# ATSAM3N00B device description
Architecture: CORTEX-M3; Family: SAM3; Series: SAM3N
Registers are 32-bit, read-write, no defined reset value unless marked. A register's access mark holds for its fields unless they carry their own. Offsets are from the block's base; [hi:lo] are bit positions; {n}, {i} and the like mark numbered series; 'fields as' and 'values as' point back to an identical list.

## EFC — Embedded Flash Controller
Instances: EFC 0x400E0A00
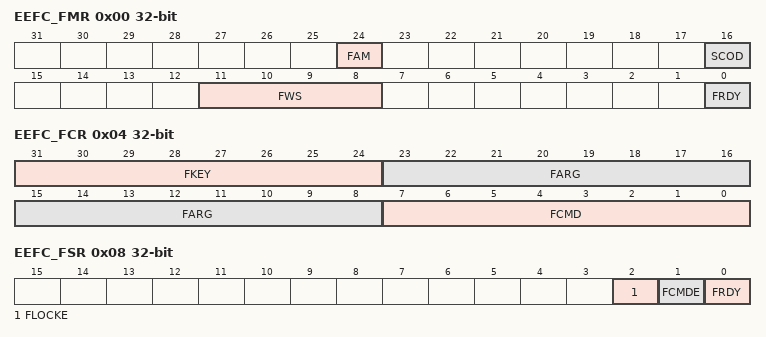
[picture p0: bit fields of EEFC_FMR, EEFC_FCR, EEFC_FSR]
0x00 EEFC_FMR — EEFC Flash Mode Register
  [24] FAM — Flash Access Mode
  [16] SCOD — Sequential Code Optimization Disable
  [11:8] FWS — Flash Wait State
  [0] FRDY — Ready Interrupt Enable
0x04 EEFC_FCR wo — EEFC Flash Command Register
  [31:24] FKEY — Flash Writing Protection Key
    90=PASSWD (The 0x5A value enables the command defined by the bits of the register. If the field is written with a different value, the write is not performed and no action is started.)
  [23:8] FARG — Flash Command Argument
  [7:0] FCMD — Flash Command
    0=GETD (Get Flash Descriptor); 1=WP (Write page); 2=WPL (Write page and lock); 3=EWP (Erase page and write page); 4=EWPL (Erase page and write page then lock); 5=EA (Erase all); 8=SLB (Set Lock Bit); 9=CLB (Clear Lock Bit); 10=GLB (Get Lock Bit); 11=SGPB (Set GPNVM Bit); 12=CGPB (Clear GPNVM Bit); 13=GGPB (Get GPNVM Bit); 14=STUI (Start Read Unique Identifier); 15=SPUI (Stop Read Unique Identifier); 16=GCALB (Get CALIB Bit)
0x08 EEFC_FSR ro — EEFC Flash Status Register
  [2] FLOCKE — Flash Lock Error Status
  [1] FCMDE — Flash Command Error Status
  [0] FRDY — Flash Ready Status
0x0C EEFC_FRR ro — EEFC Flash Result Register
  [31:0] FVALUE — Flash Result Value

## GPBR — General Purpose Backup Registers
Instances: GPBR 0x400E1490
{0x0+4i} SYS_GPBR{i} (i=0..7) — General Purpose Backup Register {i}
  [31:0] GPBR_VALUE — Value of GPBR x

## MATRIX — AHB Bus Matrix
Instances: MATRIX 0x400E0200
{0x0+4i} MATRIX_MCFG{i} (i=0..2) — Master Configuration Register {i}
  [2:0] ULBT — Undefined Length Burst Type
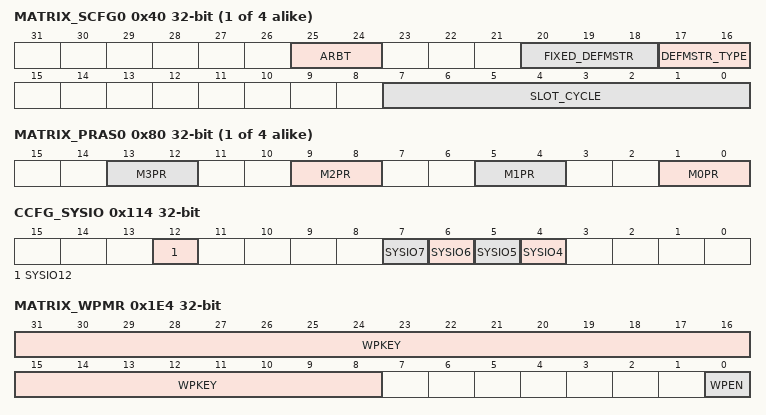
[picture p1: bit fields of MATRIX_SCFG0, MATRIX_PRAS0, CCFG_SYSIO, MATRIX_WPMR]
{0x40+4i} MATRIX_SCFG{i} (i=0..3) — Slave Configuration Register {i}
  [25:24] ARBT — Arbitration Type
  [20:18] FIXED_DEFMSTR — Fixed Default Master
  [17:16] DEFMSTR_TYPE — Default Master Type
  [7:0] SLOT_CYCLE — Maximum Number of Allowed Cycles for a Burst
{0x80+8i} MATRIX_PRAS{i} (i=0..3) — Priority Register A for Slave {i}
  [4n+1:4n] M{n}PR (n=0..3) — Master {n} Priority
0x114 CCFG_SYSIO — System I/O Configuration register
  [12] SYSIO12 — PB12 or ERASE Assignment
  [7] SYSIO7 — PB7 or TCK/SWCLK Assignment
  [6] SYSIO6 — PB6 or TMS/SWDIO Assignment
  [5] SYSIO5 — PB5 or TDO/TRACESWO Assignment
  [4] SYSIO4 — PB4 or TDI Assignment
0x1E4 MATRIX_WPMR — Write Protect Mode Register
  [31:8] WPKEY — Write Protect KEY (Write-only)
  [0] WPEN — Write Protect ENable
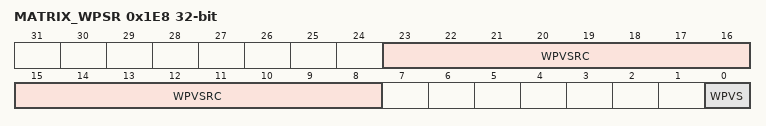
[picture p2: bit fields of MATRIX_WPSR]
0x1E8 MATRIX_WPSR ro — Write Protect Status Register
  [23:8] WPVSRC — Write Protect Violation Source
  [0] WPVS — Write Protect Violation Status

## PDC — Peripheral DMA Controller
0x00 PERIPH_RPR — Receive Pointer Register
  [31:0] RXPTR
0x04 PERIPH_RCR — Receive Counter Register
  [15:0] RXCTR
0x08 PERIPH_TPR — Transmit Pointer Register
  [31:0] TXPTR — Transmit Counter Register
0x0C PERIPH_TCR — Transmit Counter Register
  [15:0] TXCTR
0x10 PERIPH_RNPR — Receive Next Pointer Register
  [31:0] RXNPTR — Receive Next Pointer
0x14 PERIPH_RNCR — Receive Next Counter Register
  [15:0] RXNCTR — Receive Next Counter
0x18 PERIPH_TNPR — Transmit Next Pointer Register
  [31:0] TXNPTR — Transmit Next Pointer
0x1C PERIPH_TNCR — Transmit Next Counter Register
  [15:0] TXNCTR — Transmit Counter Next
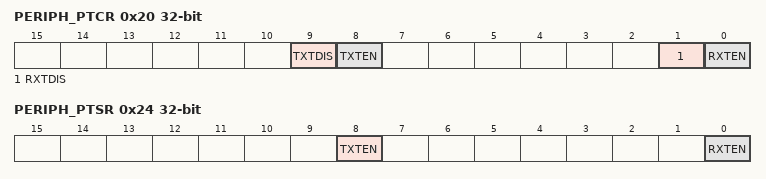
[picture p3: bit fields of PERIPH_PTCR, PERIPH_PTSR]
0x20 PERIPH_PTCR wo — Transfer Control Register
  [9] TXTDIS — Transmitter Transfer Disable
  [8] TXTEN — Transmitter Transfer Enable
  [1] RXTDIS — Receiver Transfer Disable
  [0] RXTEN — Receiver Transfer Enable
0x24 PERIPH_PTSR ro — Transfer Status Register
  [8] TXTEN — Transmitter Transfer Enable
  [0] RXTEN — Receiver Transfer Enable

## PWM — Pulse Width Modulation Controller
Instances: PWM 0x40020000
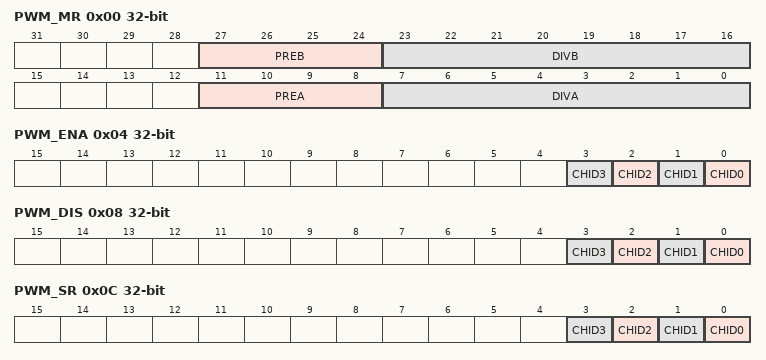
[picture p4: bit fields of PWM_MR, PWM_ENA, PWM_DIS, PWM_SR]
0x00 PWM_MR — PWM Mode Register
  [27:24] PREB
    0=MCK (Master Clock); 1=MCKDIV2 (Master Clock divided by 2); 2=MCKDIV4 (Master Clock divided by 4); 3=MCKDIV8 (Master Clock divided by 8); 4=MCKDIV16 (Master Clock divided by 16); 5=MCKDIV32 (Master Clock divided by 32); 6=MCKDIV64 (Master Clock divided by 64); 7=MCKDIV128 (Master Clock divided by 128); 8=MCKDIV256 (Master Clock divided by 256); 9=MCKDIV512 (Master Clock divided by 512); 10=MCKDIV1024 (Master Clock divided by 1024)
  [23:16] DIVB — CLKA, CLKB Divide Factor
    0=CLK_OFF (CLKA, CLKB clock is turned off); 1=CLK_DIV1 (CLKA, CLKB clock is clock selected by PREA, PREB)
  [11:8] PREA
    values as PREB
  [7:0] DIVA — CLKA, CLKB Divide Factor
    values as DIVB
0x04 PWM_ENA wo — PWM Enable Register
  [n] CHID{n} (n=0..3) — Channel ID
0x08 PWM_DIS wo — PWM Disable Register
  [n] CHID{n} (n=0..3) — Channel ID
0x0C PWM_SR ro — PWM Status Register
  [n] CHID{n} (n=0..3) — Channel ID
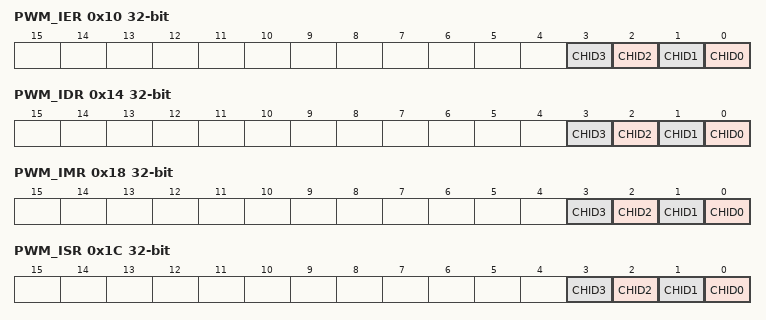
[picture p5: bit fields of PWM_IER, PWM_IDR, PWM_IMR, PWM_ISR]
0x10 PWM_IER wo — PWM Interrupt Enable Register
  [n] CHID{n} (n=0..3) — Channel ID.
0x14 PWM_IDR wo — PWM Interrupt Disable Register
  [n] CHID{n} (n=0..3) — Channel ID.
0x18 PWM_IMR ro — PWM Interrupt Mask Register
  [n] CHID{n} (n=0..3) — Channel ID.
0x1C PWM_ISR ro — PWM Interrupt Status Register
  [n] CHID{n} (n=0..3) — Channel ID
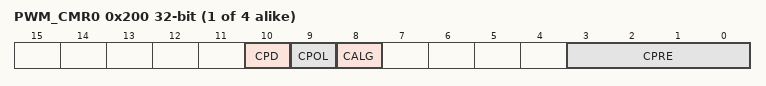
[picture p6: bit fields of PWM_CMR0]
{0x200+0x20*i} PWM_CMR{i} (i=0..3) — PWM Channel Mode Register (ch_num = {i})
  [10] CPD — Channel Update Period
  [9] CPOL — Channel Polarity
  [8] CALG — Channel Alignment
  [3:0] CPRE — Channel Pre-scaler
    0=MCK (Master Clock); 1=MCKDIV2 (Master Clock divided by 2); 2=MCKDIV4 (Master Clock divided by 4); 3=MCKDIV8 (Master Clock divided by 8); 4=MCKDIV16 (Master Clock divided by 16); 5=MCKDIV32 (Master Clock divided by 32); 6=MCKDIV64 (Master Clock divided by 64); 7=MCKDIV128 (Master Clock divided by 128); 8=MCKDIV256 (Master Clock divided by 256); 9=MCKDIV512 (Master Clock divided by 512); 10=MCKDIV1024 (Master Clock divided by 1024); 11=CLKA (Clock A); 12=CLKB (Clock B)
{0x204+0x20*i} PWM_CDTY{i} (i=0..3) — PWM Channel Duty Cycle Register (ch_num = {i})
  [31:0] CDTY — Channel Duty Cycle
{0x208+0x20*i} PWM_CPRD{i} (i=0..3) — PWM Channel Period Register (ch_num = {i})
  [31:0] CPRD — Channel Period
{0x20C+0x20*i} PWM_CCNT{i} ro (i=0..3) — PWM Channel Counter Register (ch_num = {i})
  [31:0] CNT — Channel Counter Register
{0x210+0x20*i} PWM_CUPD{i} wo (i=0..3) — PWM Channel Update Register (ch_num = {i})
  [31:0] CUPD
